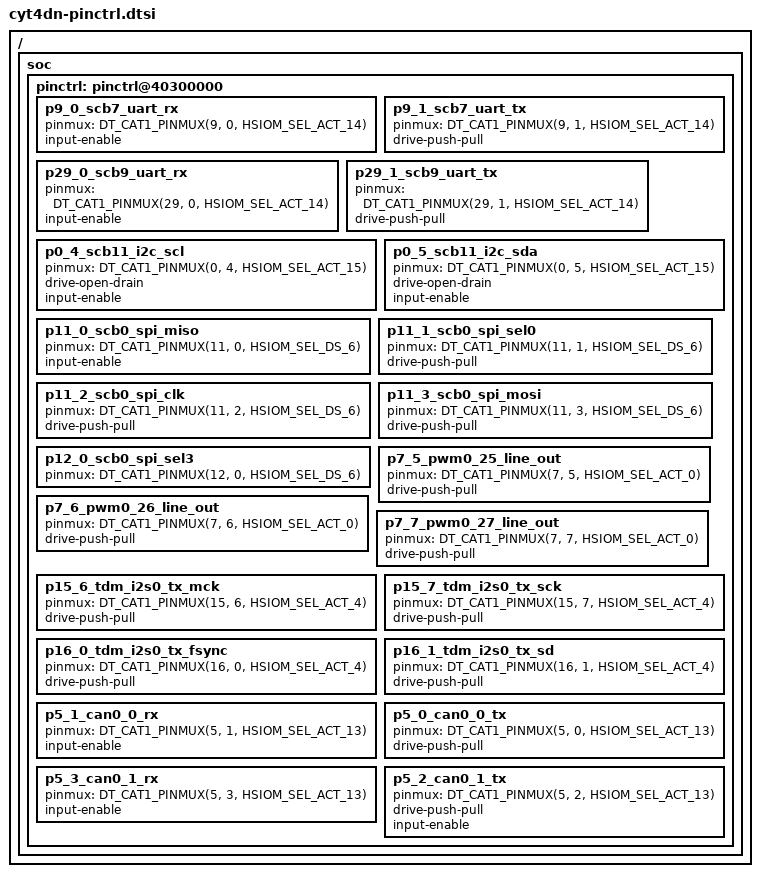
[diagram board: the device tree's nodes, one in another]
/*
 * Copyright (c) 2026 Linumiz
 *
 * SPDX-License-Identifier: Apache-2.0
 */

#include <zephyr/dt-bindings/gpio/gpio.h>
#include <zephyr/dt-bindings/pinctrl/ifx_cat1-pinctrl.h>
#include "cyt4dn.dtsi"

/ {
	soc {
		pinctrl: pinctrl@40300000 {
			/omit-if-no-ref/ p9_0_scb7_uart_rx: p9_0_scb7_uart_rx {
				pinmux = <DT_CAT1_PINMUX(9, 0, HSIOM_SEL_ACT_14)>;
				input-enable;
			};

			/omit-if-no-ref/ p9_1_scb7_uart_tx: p9_1_scb7_uart_tx {
				pinmux = <DT_CAT1_PINMUX(9, 1, HSIOM_SEL_ACT_14)>;
				drive-push-pull;
			};

			/omit-if-no-ref/ p29_0_scb9_uart_rx: p29_0_scb9_uart_rx {
				pinmux = <DT_CAT1_PINMUX(29, 0, HSIOM_SEL_ACT_14)>;
				input-enable;
			};

			/omit-if-no-ref/ p29_1_scb9_uart_tx: p29_1_scb9_uart_tx {
				pinmux = <DT_CAT1_PINMUX(29, 1, HSIOM_SEL_ACT_14)>;
				drive-push-pull;
			};

			/omit-if-no-ref/ p0_4_scb11_i2c_scl: p0_4_scb11_i2c_scl {
                                pinmux = <DT_CAT1_PINMUX(0, 4, HSIOM_SEL_ACT_15)>;
                                drive-open-drain;
                                input-enable;
                        };

                        /omit-if-no-ref/ p0_5_scb11_i2c_sda: p0_5_scb11_i2c_sda {
                                pinmux = <DT_CAT1_PINMUX(0, 5, HSIOM_SEL_ACT_15)>;
                                drive-open-drain;
                                input-enable;
			};

			/omit-if-no-ref/ p11_0_scb0_spi_miso: p11_0_scb0_spi_miso {
				pinmux = <DT_CAT1_PINMUX(11, 0, HSIOM_SEL_DS_6)>;
				input-enable;
			};

			/omit-if-no-ref/ p11_1_scb0_spi_sel0: p11_1_scb0_spi_sel0 {
				pinmux = <DT_CAT1_PINMUX(11, 1, HSIOM_SEL_DS_6)>;
				drive-push-pull;
			};

			/omit-if-no-ref/ p11_2_scb0_spi_clk: p11_2_scb0_spi_clk {
				pinmux = <DT_CAT1_PINMUX(11, 2, HSIOM_SEL_DS_6)>;
				drive-push-pull;
			};

			/omit-if-no-ref/ p11_3_scb0_spi_mosi: p11_3_scb0_spi_mosi {
				pinmux = <DT_CAT1_PINMUX(11, 3, HSIOM_SEL_DS_6)>;
				drive-push-pull;
			};

			/omit-if-no-ref/ p12_0_scb0_spi_sel3: p12_0_scb0_spi_sel3 {
				pinmux = <DT_CAT1_PINMUX(12, 0, HSIOM_SEL_DS_6)>;
			};

			/omit-if-no-ref/ p7_5_pwm0_25_line_out:  p7_5_pwm0_25_line_out {
				pinmux = <DT_CAT1_PINMUX(7, 5, HSIOM_SEL_ACT_0)>;
				drive-push-pull;
			};

			/omit-if-no-ref/ p7_6_pwm0_26_line_out:  p7_6_pwm0_26_line_out {
				pinmux = <DT_CAT1_PINMUX(7, 6, HSIOM_SEL_ACT_0)>;
				drive-push-pull;
			};

			/omit-if-no-ref/ p7_7_pwm0_27_line_out:  p7_7_pwm0_27_line_out {
				pinmux = <DT_CAT1_PINMUX(7, 7, HSIOM_SEL_ACT_0)>;
				drive-push-pull;
			};

			/omit-if-no-ref/ p15_6_tdm_i2s0_tx_mck: p15_6_tdm_i2s0_tx_mck {
                                pinmux = <DT_CAT1_PINMUX(15, 6, HSIOM_SEL_ACT_4)>;
				drive-push-pull;
                        };

                        /omit-if-no-ref/ p15_7_tdm_i2s0_tx_sck: p15_7_tdm_i2s0_tx_sck {
                                pinmux = <DT_CAT1_PINMUX(15, 7, HSIOM_SEL_ACT_4)>;
				drive-push-pull;
                        };

                        /omit-if-no-ref/ p16_0_tdm_i2s0_tx_fsync: p16_0_tdm_i2s0_tx_fsync {
                                pinmux = <DT_CAT1_PINMUX(16, 0, HSIOM_SEL_ACT_4)>;
				drive-push-pull;
                        };

                        /omit-if-no-ref/ p16_1_tdm_i2s0_tx_sd: p16_1_tdm_i2s0_tx_sd {
                                pinmux = <DT_CAT1_PINMUX(16, 1, HSIOM_SEL_ACT_4)>;
				drive-push-pull;
                        };

			/omit-if-no-ref/ p5_1_can0_0_rx: p5_1_can0_0_rx {
				pinmux = <DT_CAT1_PINMUX(5, 1, HSIOM_SEL_ACT_13)>;
				input-enable;
			};

			/omit-if-no-ref/ p5_0_can0_0_tx: p5_0_can0_0_tx {
				pinmux = <DT_CAT1_PINMUX(5, 0, HSIOM_SEL_ACT_13)>;
				drive-push-pull;
			};

			/omit-if-no-ref/ p5_3_can0_1_rx: p5_3_can0_1_rx {
				pinmux = <DT_CAT1_PINMUX(5, 3, HSIOM_SEL_ACT_13)>;
				input-enable;
			};

			/omit-if-no-ref/ p5_2_can0_1_tx: p5_2_can0_1_tx {
				pinmux = <DT_CAT1_PINMUX(5, 2, HSIOM_SEL_ACT_13)>;
				drive-push-pull;
				input-enable;
			};
		};
	};
};
